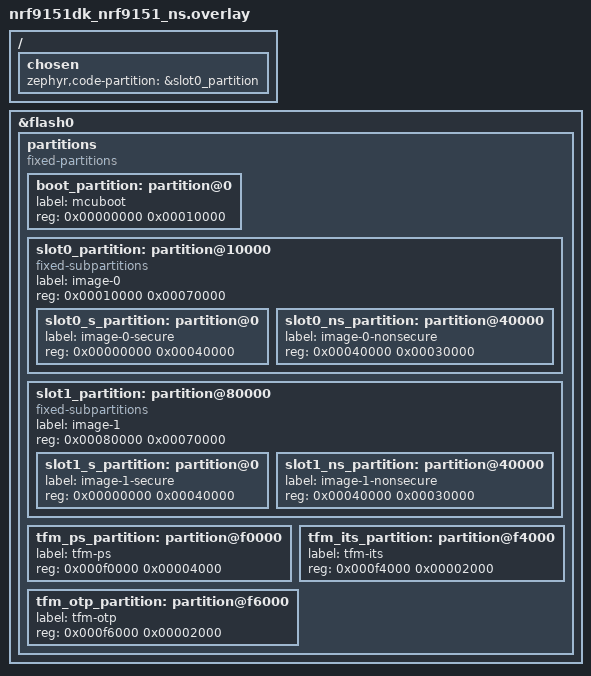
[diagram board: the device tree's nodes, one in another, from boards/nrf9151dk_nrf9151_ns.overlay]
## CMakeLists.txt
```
# Copyright (c) 2026 ID8 Engineering AB
# SPDX-License-Identifier: Apache-2.0

cmake_minimum_required(VERSION 3.13.1)
find_package(Zephyr REQUIRED HINTS $ENV{ZEPHYR_BASE})

project(app LANGUAGES C)

target_sources(app PRIVATE
  src/main.c
  ${ZEPHYR_BASE}/modules/mbedtls/zephyr_entropy.c # Mender client needs legacy crypto mbedTLS
)

# Must be compiled with the right CONFIG option to enable mbedtls_hardware_poll()
set_source_files_properties(
  ${ZEPHYR_BASE}/modules/mbedtls/zephyr_entropy.c
  PROPERTIES
  COMPILE_DEFINITIONS CONFIG_MBEDTLS_ENTROPY_POLL_ZEPHYR=1
)
```

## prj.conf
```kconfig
# Logging
CONFIG_LOG_OUTPUT_FORMAT_ISO8601_TIMESTAMP=y
CONFIG_POSIX_C_LANG_SUPPORT_R=y
CONFIG_LOG=y
CONFIG_LOG_DEFAULT_LEVEL=2
CONFIG_LOG_BUFFER_SIZE=2048

# IP / DHCP
CONFIG_NET_IPV6=n
CONFIG_NET_IPV4=y
CONFIG_NET_DHCPV4=y

# Network event notifications
CONFIG_NET_MGMT=y
CONFIG_NET_MGMT_EVENT=y
CONFIG_NET_MGMT_EVENT_STACK_SIZE=2048

# Enable TLS
CONFIG_NET_SOCKETS_SOCKOPT_TLS=y
CONFIG_NET_SOCKETS_TLS_MAX_CONTEXTS=2
CONFIG_NET_MAX_CONN=4

# DNS configuration
CONFIG_DNS_RESOLVER_ADDITIONAL_BUF_CTR=5
CONFIG_DNS_RESOLVER_ADDITIONAL_QUERIES=2
CONFIG_DNS_RESOLVER_MAX_SERVERS=2
CONFIG_DNS_NUM_CONCUR_QUERIES=5

# Avoid timeouts before receiving SYN-ACK from peer at default value (3000)
CONFIG_NET_SOCKETS_CONNECT_TIMEOUT=5000

# Memory
CONFIG_HEAP_MEM_POOL_SIZE=12288
CONFIG_MAIN_STACK_SIZE=4096
CONFIG_SYSTEM_WORKQUEUE_STACK_SIZE=4096
CONFIG_ZVFS_OPEN_MAX=5

# Modem
CONFIG_NRF_MODEM_LIB=y
CONFIG_LTE_LINK_CONTROL=y
CONFIG_MODEM_KEY_MGMT=y

# Security backend
CONFIG_NORDIC_SECURITY_BACKEND=y
CONFIG_BUILD_WITH_TFM=y
#CONFIG_ENTROPY_CC3XX=y

#Mender
CONFIG_MENDER_ARTIFACT_DOWNLOAD_RANGES=y
CONFIG_MENDER_MCU_CLIENT=y
CONFIG_MENDER_SERVER_HOST_EU=y
CONFIG_MENDER_PLATFORM_NET_TYPE_DEFAULT=y
CONFIG_MENDER_DEVICE_TYPE="nrf9151-dk-mender"
CONFIG_MENDER_LOG_LEVEL_INF=y
CONFIG_MENDER_DEPLOYMENT_LOGS=y
CONFIG_MENDER_ARTIFACT_GENERATE=y
CONFIG_MENDER_ARTIFACT_NAME="V0.1"
CONFIG_MENDER_HEAP_SIZE=16
CONFIG_MENDER_STORAGE_PARTITION_STORAGE_PARTITION=y
CONFIG_MENDER_STORAGE_NVS_SECTOR_COUNT=4
CONFIG_MENDER_SERVER_DORMANT_CERTIFICATES=n
CONFIG_MENDER_NET_CA_CERTIFICATE_TAG_SECONDARY_ENABLED=y
CONFIG_MENDER_FULL_PARSE_ARTIFACT=y
CONFIG_MENDER_CLIENT_INVENTORY_NETWORK_INFO=y # See, https://github.com/id8-engineering/nrf9151-dk-mender/issues/18
CONFIG_MENDER_PROVIDES_DEPENDS=y
CONFIG_MENDER_COMMIT_REQUIRE_AUTH=y
CONFIG_CJSON_LIB=y
CONFIG_PICOLIBC_IO_FLOAT=y

CONFIG_MBEDTLS=y
CONFIG_MBEDTLS_USE_PSA_CRYPTO=n
CONFIG_MBEDTLS_KEY_EXCHANGE_ECDHE_ECDSA_ENABLED=y
# Enable AES cipher (required for GCM cipher suites)
CONFIG_MBEDTLS_ECDH_C=y
CONFIG_MBEDTLS_ECDSA_C=y
CONFIG_MBEDTLS_ECP_C=y
# PSA crypto support (required when MBEDTLS_USE_PSA_CRYPTO is enabled)
CONFIG_PSA_WANT_ALG_ECDH=y
CONFIG_PSA_WANT_ALG_ECDSA=y
CONFIG_PSA_WANT_KEY_TYPE_ECC_PUBLIC_KEY=y
CONFIG_PSA_WANT_KEY_TYPE_ECC_KEY_PAIR_IMPORT=y
CONFIG_PSA_WANT_KEY_TYPE_ECC_KEY_PAIR_GENERATE=y
# Enable GCM support via PSA crypto
CONFIG_PSA_WANT_ALG_GCM=y
CONFIG_PSA_WANT_KEY_TYPE_AES=y
CONFIG_MBEDTLS_GENPRIME_ENABLED=y
CONFIG_MBEDTLS_PK_WRITE_C=y
CONFIG_MBEDTLS_ENABLE_HEAP=y
CONFIG_MBEDTLS_HEAP_SIZE=32768
CONFIG_MBEDTLS_ENTROPY_C=y


CONFIG_MBEDTLS_TLS_LIBRARY=y
CONFIG_MBEDTLS_X509_LIBRARY=y
CONFIG_MBEDTLS_MD_C=y
CONFIG_MBEDTLS_PK_C=y
CONFIG_MBEDTLS_PK_PARSE_C=y
CONFIG_MBEDTLS_PEM_WRITE_C=y
CONFIG_MBEDTLS_CTR_DRBG_ENABLED=y
CONFIG_MBEDTLS_CTR_DRBG_C=y
CONFIG_MBEDTLS_SHA256_C=y
CONFIG_MBEDTLS_SSL_IN_CONTENT_LEN=4096
# force off problematic families for TF-M
CONFIG_MBEDTLS_KEY_EXCHANGE_ECDHE_PSK_ENABLED=n
CONFIG_MBEDTLS_KEY_EXCHANGE_ECDHE_RSA_ENABLED=n
CONFIG_MBEDTLS_KEY_EXCHANGE_DHE_PSK_ENABLED=n
CONFIG_MBEDTLS_KEY_EXCHANGE_DHE_RSA_ENABLED=n
CONFIG_MBEDTLS_SSL_CONTEXT_SERIALIZATION=n

#nrf
CONFIG_SOC_FLASH_NRF_EMULATE_ONE_BYTE_WRITE_ACCESS=y
```

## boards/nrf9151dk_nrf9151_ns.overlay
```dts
// Copyright (c) 2026 ID8 Engineering AB
// SPDX-License-Identifier: Apache-2.0

/ {
	chosen {
		zephyr,code-partition = &slot0_partition;
	};
};

&flash0 {
	partitions {
		compatible = "fixed-partitions";
		#address-cells = <1>;
		#size-cells = <1>;

		boot_partition: partition@0 {
			label = "mcuboot";
			reg = <0x00000000 0x00010000>;
		};

		slot0_partition: partition@10000 {
			compatible = "fixed-subpartitions";
			label = "image-0";
			reg = <0x00010000 0x00070000>;
			ranges = <0x0 0x00010000 0x00070000>;
			#address-cells = <1>;
			#size-cells = <1>;

			slot0_s_partition: partition@0 {
				label = "image-0-secure";
				reg = <0x00000000 0x00040000>;
			};

			slot0_ns_partition: partition@40000 {
				label = "image-0-nonsecure";
				reg = <0x00040000 0x00030000>;
			};
		};

		slot1_partition: partition@80000 {
			compatible = "fixed-subpartitions";
			label = "image-1";
			reg = <0x00080000 0x00070000>;
			ranges = <0x0 0x00080000 0x00070000>;
			#address-cells = <1>;
			#size-cells = <1>;

			slot1_s_partition: partition@0 {
				label = "image-1-secure";
				reg = <0x00000000 0x00040000>;
			};

			slot1_ns_partition: partition@40000 {
				label = "image-1-nonsecure";
				reg = <0x00040000 0x00030000>;
			};
		};

		tfm_ps_partition: partition@f0000 {
			label = "tfm-ps";
			reg = <0x000f0000 0x00004000>;
		};

		tfm_its_partition: partition@f4000 {
			label = "tfm-its";
			reg = <0x000f4000 0x00002000>;
		};

		tfm_otp_partition: partition@f6000 {
			label = "tfm-otp";
			reg = <0x000f6000 0x00002000>;
		};
	};
};
```

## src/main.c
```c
// Copyright (c) 2026 ID8 Engineering AB
// SPDX-License-Identifier: Apache-2.0

#include <errno.h>

#include <zephyr/kernel.h>
#include <zephyr/logging/log.h>
#include <zephyr/sys/reboot.h>
#include <zephyr/dfu/mcuboot.h>

#include <modem/lte_lc.h>
#include <modem/nrf_modem_lib.h>

#include <mender/client.h>
#include <mender/zephyr-image-update-module.h>

LOG_MODULE_REGISTER(main, LOG_LEVEL_INF);

static mender_identity_t mender_identity = {
	.name = "device_id",
	.value = "nrf9151dk",
};

static mender_err_t mender_network_connect_cb(void)
{
	return MENDER_OK;
}

static mender_err_t mender_network_release_cb(void)
{
	return MENDER_OK;
}

static mender_err_t mender_deployment_status_cb(mender_deployment_status_t status, const char *desc)
{
	ARG_UNUSED(status);
	ARG_UNUSED(desc);
	return MENDER_OK;
}

static mender_err_t mender_restart_cb(void)
{
	LOG_WRN("Mender requested reboot; waiting 5s for logs");
	k_sleep(K_SECONDS(5));
	sys_reboot(SYS_REBOOT_COLD);
	return MENDER_OK;
}

static mender_err_t mender_get_identity_cb(const mender_identity_t **identity)
{
	*identity = &mender_identity;
	return MENDER_OK;
}

int main(void)
{
	int err;

	LOG_INF("Starting LTE");

	err = nrf_modem_lib_init();
	if (err < 0) {
		LOG_ERR("Modem init failed: %d", err);
		return err;
	}

	err = lte_lc_connect();
	if (err < 0) {
		LOG_ERR("LTE connect failed: %d", err);
		return err;
	}

	LOG_INF("LTE connected");

	mender_client_config_t mender_config = {
		.recommissioning = false,
	};

	mender_client_callbacks_t mender_callbacks = {
		.network_connect = mender_network_connect_cb,
		.network_release = mender_network_release_cb,
		.deployment_status = mender_deployment_status_cb,
		.restart = mender_restart_cb,
		.get_identity = mender_get_identity_cb,
	};

	if (mender_client_init(&mender_config, &mender_callbacks) != MENDER_OK) {
		LOG_ERR("Mender init failed");
		return -EIO;
	}

#ifdef CONFIG_MENDER_ZEPHYR_IMAGE_UPDATE_MODULE
	if (mender_zephyr_image_register_update_module() != MENDER_OK) {
		LOG_ERR("Mender update module registration failed");
		return err;
	}
#endif

	if (mender_client_activate() != MENDER_OK) {
		LOG_ERR("Mender activate failed");
		return err;
	}

	LOG_INF("Mender activated");

	LOG_INF(" V0.1");

	while (1) {
		k_sleep(K_SECONDS(10));
	}

	return 0;
}
```

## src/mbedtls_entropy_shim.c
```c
#include <stdint.h>
#include <stddef.h>

#include <zephyr/random/random.h>
#include <zephyr/sys/util.h>

#include <mbedtls/entropy.h>

int mbedtls_hardware_poll(void *data, unsigned char *output, size_t len, size_t *olen)
{
	ARG_UNUSED(data);

	if ((output == NULL) || (olen == NULL) || (len == 0U)) {
		return MBEDTLS_ERR_ENTROPY_SOURCE_FAILED;
	}

	if (sys_csrand_get(output, len) != 0) {
		return MBEDTLS_ERR_ENTROPY_SOURCE_FAILED;
	}

	*olen = len;
	return 0;
}
```

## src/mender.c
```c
// Copyright (c) 2026 ID8 Engineering AB
// SPDX-License-Identifier: Apache-2.0

#include <errno.h>
#include <stddef.h>

#include <modem/lte_lc.h>
#include <modem/modem_key_mgmt.h>
#include <modem/nrf_modem_lib.h>
#include <zephyr/storage/flash_map.h>
#include <zephyr/logging/log.h>
#include <zephyr/sys/reboot.h>

#include <mender/client.h>
#include <mender/zephyr-image-update-module.h>
#include <pm_config.h>

LOG_MODULE_REGISTER(mender_app, LOG_LEVEL_INF);

#ifndef CONFIG_MENDER_NET_CA_CERTIFICATE_TAG_PRIMARY
#define CONFIG_MENDER_NET_CA_CERTIFICATE_TAG_PRIMARY 1
#endif

#ifndef CONFIG_MENDER_NET_CA_CERTIFICATE_TAG_SECONDARY
#define CONFIG_MENDER_NET_CA_CERTIFICATE_TAG_SECONDARY 2
#endif

static char mender_identity_value[] = "nrf9151-dk-mender";
static mender_identity_t mender_identity = {
	.name = "device_id",
	.value = mender_identity_value,
};
static const unsigned char mender_ca_certificate[] =
#include "isrg_root_x1.pem.inc"
	;
static const unsigned char mender_artifact_ca_certificate[] =
#include "gts_root_r4.pem.inc"
	;
static bool lte_connected;
static K_MUTEX_DEFINE(lte_lock);

static int provision_ca_certificate(uint32_t tag, const unsigned char *certificate,
				    size_t certificate_len, const char *label)
{
	int ret;
	bool exists;
	int mismatch;

	ret = modem_key_mgmt_exists(tag, MODEM_KEY_MGMT_CRED_TYPE_CA_CHAIN, &exists);
	if (ret) {
		LOG_ERR("Failed to check %s: %d", label, ret);
		return ret;
	}

	if (exists) {
		mismatch = modem_key_mgmt_cmp(tag, MODEM_KEY_MGMT_CRED_TYPE_CA_CHAIN, certificate,
					      certificate_len);
		if (mismatch == 0) {
			return 0;
		}
		if (mismatch < 0) {
			LOG_ERR("Failed to compare %s: %d", label, mismatch);
			return mismatch;
		}

		ret = modem_key_mgmt_delete(tag, MODEM_KEY_MGMT_CRED_TYPE_CA_CHAIN);
		if (ret) {
			LOG_ERR("Failed to delete old %s: %d", label, ret);
			return ret;
		}
	}

	ret = modem_key_mgmt_write(tag, MODEM_KEY_MGMT_CRED_TYPE_CA_CHAIN, certificate,
				   certificate_len);
	if (ret) {
		LOG_ERR("Failed to write %s: %d", label, ret);
		return ret;
	}

	return 0;
}

static int provision_mender_ca_certificates(void)
{
	int ret;

	ret = provision_ca_certificate(CONFIG_MENDER_NET_CA_CERTIFICATE_TAG_PRIMARY,
				       mender_ca_certificate, sizeof(mender_ca_certificate),
				       "Mender API CA certificate");
	if (ret) {
		return ret;
	}

	ret = provision_ca_certificate(
		CONFIG_MENDER_NET_CA_CERTIFICATE_TAG_SECONDARY, mender_artifact_ca_certificate,
		sizeof(mender_artifact_ca_certificate), "Mender artifact CA certificate");
	if (ret) {
		return ret;
	}

	return 0;
}

static mender_err_t mender_network_connect_cb(void)
{
	int err;

	k_mutex_lock(&lte_lock, K_FOREVER);

	if (lte_connected) {
		k_mutex_unlock(&lte_lock);
		return MENDER_OK;
	}

	LOG_INF("Connecting to LTE network");
	err = lte_lc_connect();
	if (err) {
		LOG_ERR("LTE attach failed: %d", err);
		k_mutex_unlock(&lte_lock);
		return MENDER_FAIL;
	}

	lte_connected = true;
	LOG_INF("LTE network connected");
	k_mutex_unlock(&lte_lock);

	return MENDER_OK;
}

static mender_err_t mender_network_release_cb(void)
{
	/* Keep LTE attached between requests to avoid reconnect churn. */
	return MENDER_OK;
}

static mender_err_t mender_restart_cb(void)
{
	LOG_INF("Mender requested restart");
	sys_reboot(SYS_REBOOT_COLD);
	return MENDER_OK;
}

static mender_err_t mender_deployment_status_cb(mender_deployment_status_t status,
						const char *status_name)
{
	ARG_UNUSED(status);
	LOG_INF("Mender deployment status: %s", status_name);
	return MENDER_OK;
}

static mender_err_t mender_get_identity_cb(const mender_identity_t **identity)
{
	if (identity == NULL) {
		return MENDER_FAIL;
	}

	*identity = &mender_identity;
	return MENDER_OK;
}

mender_err_t mender_get_storage_spec(const struct device **dev, int *part_id,
				     uint16_t *sector_offset)
{
	const struct flash_area *fa;
	int ret;

	if ((dev == NULL) || (part_id == NULL) || (sector_offset == NULL)) {
		return MENDER_FAIL;
	}

	ret = flash_area_open(PM_NVS_STORAGE_ID, &fa);
	if (ret != 0) {
		LOG_ERR("Unable to open NVS storage flash area: %d", ret);
		return MENDER_FAIL;
	}

	*dev = flash_area_get_device(fa);
	*part_id = PM_NVS_STORAGE_ID;
	*sector_offset = 0;
	flash_area_close(fa);

	return MENDER_OK;
}

int mender_start(void)
{
	int modem_ret;
	mender_err_t ret;
	mender_client_config_t config = {
		.device_type = CONFIG_MENDER_DEVICE_TYPE,
		.host = CONFIG_MENDER_SERVER_HOST,
		.tenant_token = CONFIG_MENDER_SERVER_TENANT_TOKEN,
		.device_tier = NULL,
		.update_poll_interval = 0,
#ifndef CONFIG_MENDER_CLIENT_INVENTORY_DISABLE
		.inventory_update_interval = 0,
#endif
		.backoff_interval = 0,
		.max_backoff_interval = 0,
		.recommissioning = false,
	};
	mender_client_callbacks_t callbacks = {
		.network_connect = mender_network_connect_cb,
		.network_release = mender_network_release_cb,
		.deployment_status = mender_deployment_status_cb,
		.restart = mender_restart_cb,
		.get_identity = mender_get_identity_cb,
		.get_user_provided_keys = NULL,
	};

	modem_ret = nrf_modem_lib_init();
	if (modem_ret) {
		LOG_ERR("Modem library initialization failed: %d", modem_ret);
		return -EINVAL;
	}

	modem_ret = provision_mender_ca_certificates();
	if (modem_ret) {
		return -EINVAL;
	}

	ret = mender_client_init(&config, &callbacks);
	if (ret != MENDER_OK) {
		LOG_ERR("Mender init failed: %d", ret);
		return -EINVAL;
	}

	ret = mender_zephyr_image_register_update_module();
	if (ret != MENDER_OK) {
		LOG_ERR("Mender update module registration failed: %d", ret);
		return -EINVAL;
	}

	ret = mender_client_activate();
	if (ret != MENDER_OK) {
		LOG_ERR("Mender activation failed: %d", ret);
		return -EINVAL;
	}

	LOG_INF("Mender activated");
	return 0;
}
```

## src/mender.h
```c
// Copyright (c) 2026 ID8 Engineering AB
// SPDX-License-Identifier: Apache-2.0

#ifndef MENDER_H_
#define MENDER_H_

int mender_start(void);

#endif /* MENDER_H_ */
```
